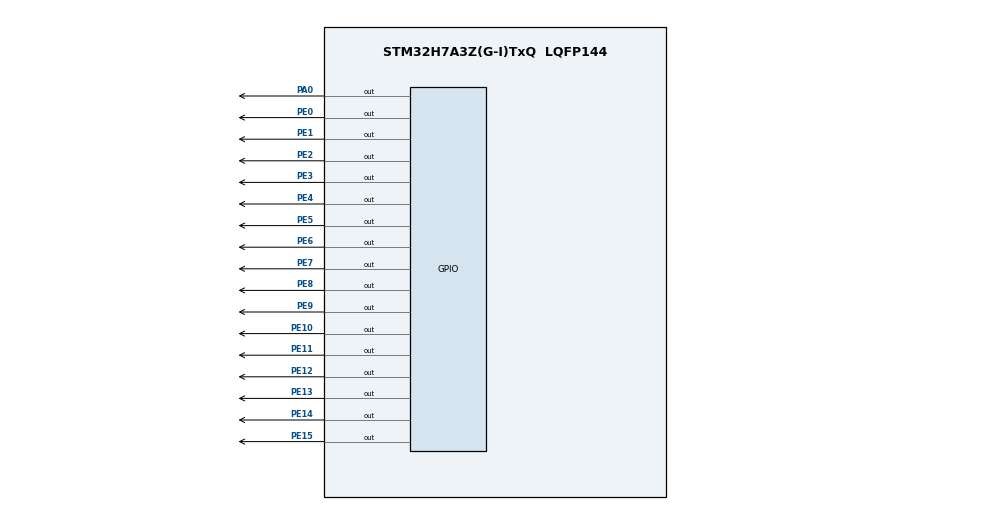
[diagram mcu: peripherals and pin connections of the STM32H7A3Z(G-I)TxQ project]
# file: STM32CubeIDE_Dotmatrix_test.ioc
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Mcu.Family=STM32H7
Mcu.Name=STM32H7A3Z(G-I)TxQ
Mcu.Package=LQFP144
NVIC.PriorityGroup=NVIC_PRIORITYGROUP_4
PA0.Signal=GPIO_Output
PE0.Signal=GPIO_Output
PE1.Signal=GPIO_Output
PE10.Signal=GPIO_Output
PE11.Signal=GPIO_Output
PE12.Signal=GPIO_Output
PE13.Signal=GPIO_Output
PE14.Signal=GPIO_Output
PE15.Signal=GPIO_Output
PE2.Signal=GPIO_Output
PE3.Signal=GPIO_Output
PE4.Signal=GPIO_Output
PE5.Signal=GPIO_Output
PE6.Signal=GPIO_Output
PE7.Signal=GPIO_Output
PE8.Signal=GPIO_Output
PE9.Signal=GPIO_Output
PH0-OSC_IN.Mode=HSE-External-Oscillator
PH0-OSC_IN.Signal=RCC_OSC_IN
PH1-OSC_OUT.Mode=HSE-External-Oscillator
PH1-OSC_OUT.Signal=RCC_OSC_OUT
ProjectManager.HeapSize=0x200
ProjectManager.StackSize=0x400
ProjectManager.TargetToolchain=STM32CubeIDE
RCC.ADCFreq_Value=129000000
RCC.APB1Freq_Value=64000000
RCC.APB2Freq_Value=64000000
RCC.APB3Freq_Value=64000000
RCC.APB4Freq_Value=64000000
RCC.CortexFreq_Value=64000000
RCC.HCLKFreq_Value=64000000
RCC.SYSCLKFreq_VALUE=64000000
RCC.USBFreq_Value=129000000
board=custom

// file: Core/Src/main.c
/* USER CODE BEGIN Header */
/**
  ******************************************************************************
  * @file           : main.c
  * @brief          : Main program body
  ******************************************************************************
  * @attention
  *
  * Copyright (c) 2023 STMicroelectronics.
  * All rights reserved.
  *
  * This software is licensed under terms that can be found in the LICENSE file
  * in the root directory of this software component.
  * If no LICENSE file comes with this software, it is provided AS-IS.
  *
  ******************************************************************************
  */
/* USER CODE END Header */
#include "main.h"
#include "gpio.h"

/* USER CODE BEGIN Includes */
#include "_7_seg.h"
/* USER CODE END Includes */

void SystemClock_Config(void);

int main(void)
{

  /* MCU Configuration--------------------------------------------------------*/

  /* Reset of all peripherals, Initializes the Flash interface and the Systick. */
  HAL_Init();

  /* Configure the system clock */
  SystemClock_Config();

  /* Initialize all configured peripherals */
  MX_GPIO_Init();

  /* Infinite loop */
  /* USER CODE BEGIN WHILE */
  while (1)
  {
	  if(HAL_GPIO_ReadPin(GPIOA, GPIO_PIN_0)==1)
	  {
		  Dot_right();
	  }
	  if(HAL_GPIO_ReadPin(GPIOA, GPIO_PIN_0)==0)
	  {
		  Dot_left();
	  }

    /* USER CODE END WHILE */

  }
}

void SystemClock_Config(void)
{
  RCC_OscInitTypeDef RCC_OscInitStruct = {0};
  RCC_ClkInitTypeDef RCC_ClkInitStruct = {0};

  /** Supply configuration update enable
  */
  HAL_PWREx_ConfigSupply(PWR_DIRECT_SMPS_SUPPLY);
  /** Configure the main internal regulator output voltage
  */
  __HAL_PWR_VOLTAGESCALING_CONFIG(PWR_REGULATOR_VOLTAGE_SCALE3);

  while(!__HAL_PWR_GET_FLAG(PWR_FLAG_VOSRDY)) {}
  /** Initializes the RCC Oscillators according to the specified parameters
  * in the RCC_OscInitTypeDef structure.
  */
  RCC_OscInitStruct.OscillatorType = RCC_OSCILLATORTYPE_HSI;
  RCC_OscInitStruct.HSIState = RCC_HSI_DIV1;
  RCC_OscInitStruct.HSICalibrationValue = RCC_HSICALIBRATION_DEFAULT;
  RCC_OscInitStruct.PLL.PLLState = RCC_PLL_NONE;
  if (HAL_RCC_OscConfig(&RCC_OscInitStruct) != HAL_OK)
  {
    Error_Handler();
  }
  /** Initializes the CPU, AHB and APB buses clocks
  */
  RCC_ClkInitStruct.ClockType = RCC_CLOCKTYPE_HCLK|RCC_CLOCKTYPE_SYSCLK
                              |RCC_CLOCKTYPE_PCLK1|RCC_CLOCKTYPE_PCLK2
                              |RCC_CLOCKTYPE_D3PCLK1|RCC_CLOCKTYPE_D1PCLK1;
  RCC_ClkInitStruct.SYSCLKSource = RCC_SYSCLKSOURCE_HSI;
  RCC_ClkInitStruct.SYSCLKDivider = RCC_SYSCLK_DIV1;
  RCC_ClkInitStruct.AHBCLKDivider = RCC_HCLK_DIV1;
  RCC_ClkInitStruct.APB3CLKDivider = RCC_APB3_DIV1;
  RCC_ClkInitStruct.APB1CLKDivider = RCC_APB1_DIV1;
  RCC_ClkInitStruct.APB2CLKDivider = RCC_APB2_DIV1;
  RCC_ClkInitStruct.APB4CLKDivider = RCC_APB4_DIV1;

  if (HAL_RCC_ClockConfig(&RCC_ClkInitStruct, FLASH_LATENCY_2) != HAL_OK)
  {
    Error_Handler();
  }
}

void Error_Handler(void)
{
  __disable_irq();
  while (1)
  {
  }
}
